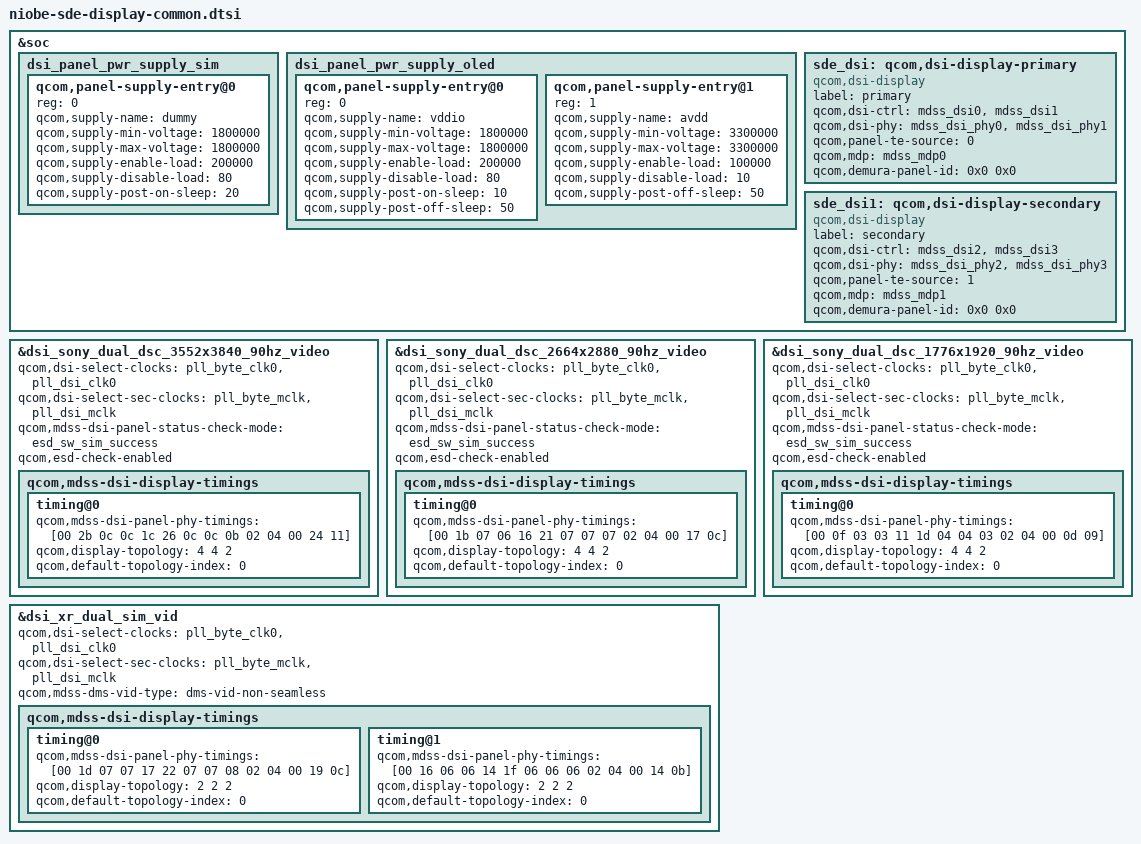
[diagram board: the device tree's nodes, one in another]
#include "dsi-panel-sony-dualmipi-dsc-3552x3840-video.dtsi"
#include "dsi-panel-sony-dualmipi-dsc-2664x2880-video.dtsi"
#include "dsi-panel-sony-dualmipi-dsc-1776x1920-video.dtsi"
#include "dsi-xr-panel-sim-dualmipi-video.dtsi"

&soc {
	dsi_panel_pwr_supply_sim: dsi_panel_pwr_supply_sim {
		#address-cells = <1>;
		#size-cells = <0>;

		qcom,panel-supply-entry@0 {
			reg = <0>;
			qcom,supply-name = "dummy";
			qcom,supply-min-voltage = <1800000>;
			qcom,supply-max-voltage = <1800000>;
			qcom,supply-enable-load = <200000>;
			qcom,supply-disable-load = <80>;
			qcom,supply-post-on-sleep = <20>;
		};
	};

	dsi_panel_pwr_supply_oled: dsi_panel_pwr_supply_oled {
		#address-cells = <1>;
		#size-cells = <0>;

		qcom,panel-supply-entry@0 {
			reg = <0>;
			qcom,supply-name = "vddio";
			qcom,supply-min-voltage = <1800000>;
			qcom,supply-max-voltage = <1800000>;
			qcom,supply-enable-load = <200000>;
			qcom,supply-disable-load = <80>;
			qcom,supply-post-on-sleep = <10>;
			qcom,supply-post-off-sleep = <50>;
		};

		qcom,panel-supply-entry@1 {
			reg = <1>;
			qcom,supply-name = "avdd";
			qcom,supply-min-voltage = <3300000>;
			qcom,supply-max-voltage = <3300000>;
			qcom,supply-enable-load = <100000>;
			qcom,supply-disable-load = <10>;
			qcom,supply-post-off-sleep = <50>;
		};
	};

	sde_dsi: qcom,dsi-display-primary {
		compatible = "qcom,dsi-display";
		label = "primary";

		qcom,dsi-ctrl = <&mdss_dsi0 &mdss_dsi1>;
		qcom,dsi-phy = <&mdss_dsi_phy0 &mdss_dsi_phy1>;

		qcom,panel-te-source = <0>;

		qcom,mdp = <&mdss_mdp0>;
		qcom,demura-panel-id = <0x0 0x0>;
	};

	sde_dsi1: qcom,dsi-display-secondary {
		compatible = "qcom,dsi-display";
		label = "secondary";

		qcom,dsi-ctrl = <&mdss_dsi2 &mdss_dsi3>;
		qcom,dsi-phy = <&mdss_dsi_phy2 &mdss_dsi_phy3>;

		qcom,panel-te-source = <1>;

		qcom,mdp = <&mdss_mdp1>;
		qcom,demura-panel-id = <0x0 0x0>;
	};
};

/* PHY TIMINGS REVISION YK with reduced margins*/
&dsi_sony_dual_dsc_3552x3840_90hz_video {
	qcom,dsi-select-clocks = "pll_byte_clk0", "pll_dsi_clk0";
	qcom,dsi-select-sec-clocks = "pll_byte_mclk", "pll_dsi_mclk";

	qcom,mdss-dsi-panel-status-check-mode = "esd_sw_sim_success";
	qcom,esd-check-enabled;

	qcom,mdss-dsi-display-timings {
		timing@0 {
			qcom,mdss-dsi-panel-phy-timings = [00 2b 0c 0c 1c 26 0c
				0c 0b 02 04 00 24 11];
			qcom,display-topology = <4 4 2>;
			qcom,default-topology-index = <0>;
		};
	};
};

&dsi_sony_dual_dsc_2664x2880_90hz_video {
	qcom,dsi-select-clocks = "pll_byte_clk0", "pll_dsi_clk0";
	qcom,dsi-select-sec-clocks = "pll_byte_mclk", "pll_dsi_mclk";

	qcom,mdss-dsi-panel-status-check-mode = "esd_sw_sim_success";
	qcom,esd-check-enabled;

	qcom,mdss-dsi-display-timings {
		timing@0 {
			qcom,mdss-dsi-panel-phy-timings = [00 1b 07 06 16 21 07
				07 07 02 04 00 17 0c];
			qcom,display-topology = <4 4 2>;
			qcom,default-topology-index = <0>;
		};
	};
};

&dsi_sony_dual_dsc_1776x1920_90hz_video {
	qcom,dsi-select-clocks = "pll_byte_clk0", "pll_dsi_clk0";
	qcom,dsi-select-sec-clocks = "pll_byte_mclk", "pll_dsi_mclk";

	qcom,mdss-dsi-panel-status-check-mode = "esd_sw_sim_success";
	qcom,esd-check-enabled;

	qcom,mdss-dsi-display-timings {
		timing@0 {
			qcom,mdss-dsi-panel-phy-timings = [00 0f 03 03 11 1d 04
				04 03 02 04 00 0d 09];
			qcom,display-topology = <4 4 2>;
			qcom,default-topology-index = <0>;
		};
	};
};

&dsi_xr_dual_sim_vid {
	qcom,dsi-select-clocks = "pll_byte_clk0", "pll_dsi_clk0";
	qcom,dsi-select-sec-clocks = "pll_byte_mclk", "pll_dsi_mclk";
	qcom,mdss-dms-vid-type = "dms-vid-non-seamless";

	qcom,mdss-dsi-display-timings {
		timing@0 {
			qcom,mdss-dsi-panel-phy-timings = [00 1d 07 07 17 22 07
				07 08 02 04 00 19 0c];
			qcom,display-topology = <2 2 2>;
			qcom,default-topology-index = <0>;
		};
		timing@1 {
			qcom,mdss-dsi-panel-phy-timings = [00 16 06 06 14 1f 06
				06 06 02 04 00 14 0b];
			qcom,display-topology = <2 2 2>;
			qcom,default-topology-index = <0>;
		};
	};
};
